# MKE16Z4 register map
Vendor: nxp.com; File version: 1.0
CPU: CM0PLUS r0p0, little endian, no MPU, no FPU, VTOR, 2 interrupt priority bits
Registers are 32-bit, read-write, reset 0x0 unless marked. A register's access mark holds for its fields unless they carry their own. Offsets are from the block's base; [hi:lo] are bit positions; {n}, {i} and the like mark numbered series; 'fields as' and 'values as' point back to an identical list.

## MSCAN — Modular/Scalable Controller Area Network (MSCAN)
Base 0x40024000; register names take the prefix MSCAN_
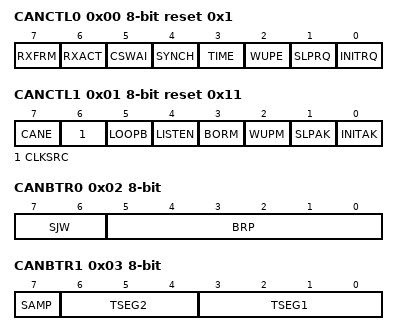
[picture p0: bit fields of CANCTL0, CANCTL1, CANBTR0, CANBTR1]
0x00 CANCTL0 8-bit reset 0x1 — MSCAN Control Register 0
  [7] RXFRM — Received Frame Flag
    0=No valid message was received since last clearing this flag; 1=A valid message was received since last clearing of this flag
  [6] RXACT ro — Receiver Active Status
    0=MSCAN is transmitting or idle; 1=MSCAN is receiving a message, including when arbitration is lost
  [5] CSWAI — CAN Stops in Wait Mode
    0=The module is not affected during wait mode; 1=The module ceases to be clocked during wait mode
  [4] SYNCH ro — Synchronized Status
    0=MSCAN is not synchronized to the CAN bus; 1=MSCAN is synchronized to the CAN bus
  [3] TIME — Timer Enable
    0=Disable internal MSCAN timer; 1=Enable internal MSCAN timer
  [2] WUPE — WakeUp Enable
    0=Wakeup disabled - The MSCAN ignores traffic on CAN; 1=Wakeup enabled - The MSCAN is able to restart
  [1] SLPRQ — Sleep Mode Request
    0=Running - The MSCAN functions normally; 1=Sleep mode request - The MSCAN enters sleep mode when CAN bus idle
  [0] INITRQ — Initialization Mode Request
    0=Normal operation; 1=MSCAN in initialization mode
0x01 CANCTL1 8-bit reset 0x11 — MSCAN Control Register 1
  [7] CANE — MSCAN Enable
    0=MSCAN module is disabled; 1=MSCAN module is enabled
  [6] CLKSRC — MSCAN Clock Source
    0=MSCAN clock source is the oscillator clock; 1=MSCAN clock source is the bus clock
  [5] LOOPB — Loopback Self Test Mode
    0=Loopback self test disabled; 1=Loopback self test enabled
  [4] LISTEN — Listen Only Mode
    0=Normal operation; 1=Listen only mode activated
  [3] BORM — Bus-Off Recovery Mode
    0=Automatic bus-off recovery (see Bosch CAN 2.0A/B protocol specification); 1=Bus-off recovery upon user request
  [2] WUPM — WakeUp Mode
    0=MSCAN wakes on any dominant level on the CAN bus; 1=MSCAN wakes only in case of a dominant pulse on the CAN bus that has a length of Twup
  [1] SLPAK ro — Sleep Mode Acknowledge
    0=Running - The MSCAN operates normally; 1=Sleep mode active - The MSCAN has entered sleep mode
  [0] INITAK ro — Initialization Mode Acknowledge
    0=Running - The MSCAN operates normally; 1=Initialization mode active - The MSCAN has entered initialization mode
0x02 CANBTR0 8-bit — MSCAN Bus Timing Register 0
  [7:6] SJW — Synchronization Jump Width
    0=1 Tq clock cycle; 1=2 Tq clock cycles; 2=3 Tq clock cycle; 3=4 Tq clock cycles
  [5:0] BRP — Baud Rate Prescaler
    0=1; 1=2; 2=BRP_2; 3=BRP_3; 62=63; 63=64
0x03 CANBTR1 8-bit — MSCAN Bus Timing Register 1
  [7] SAMP — Sampling
    0=One sample per bit; 1=Three samples per bit. In this case, PHASE_SEG1 must be at least 2 time quanta (Tq).
  [6:4] TSEG2 — Time Segment 2
    0=1 Tq clock cycle (not valid); {v}={v+1} Tq clock cycles (v=1..7)
  [3:0] TSEG1 — Time Segment 1
    0=1 Tq clock cycle (not valid); 1=2 Tq clock cycles (not valid); 2=3 Tq clock cycles (not valid); 3=4 Tq clock cycles; 14=15 Tq clock cycles; 15=16 Tq clock cycles
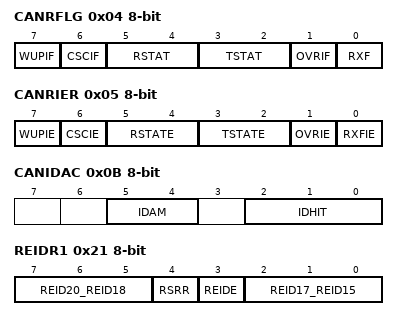
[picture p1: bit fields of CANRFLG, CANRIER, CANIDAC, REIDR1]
0x04 CANRFLG 8-bit — MSCAN Receiver Flag Register
  [7] WUPIF — Wake-Up Interrupt Flag
    0=No wakeup activity observed while in sleep mode; 1=MSCAN detected activity on the CAN bus and requested wakeup
  [6] CSCIF — CAN Status Change Interrupt Flag
    0=No change in CAN bus status occurred since last interrupt; 1=MSCAN changed current CAN bus status
  [5:4] RSTAT ro — Receiver Status
    0=RxOK: 0<=receive error counter<96; 1=RxWRN: 96<=receive error counter<128; 2=RxERR: 128<=receive error counter; 3=Bus-off: 256<=transmit error counter (Redundant Information for the most critical CAN bus status which is "bus-off". This only occurs if the Tx error counter exceeds a number of 255 errors. Bus-off affects the receiver state. As soon as the transmitter leaves its bus-off state the receiver state skips to RxOK too. Refer also to TSTAT[1:0] coding in this register. )
  [3:2] TSTAT ro — Transmitter Status
    0=TxOK: 0<=transmit error counter<96; 1=TxWRN: 96<=transmit error counter<128; 2=TxERR: 128<=transmit error counter<256; 3=Bus-off: 256<=transmit error counter
  [1] OVRIF — Overrun Interrupt Flag
    0=No data overrun condition; 1=A data overrun detected
  [0] RXF — Receive Buffer Full Flag
    0=No new message available within the RxFG; 1=The receiver FIFO is not empty. A new message is available in the RxFG.
0x05 CANRIER 8-bit — MSCAN Receiver Interrupt Enable Register
  [7] WUPIE — WakeUp Interrupt Enable
    0=No interrupt request is generated from this event; 1=A wake-up event causes a Wake-Up interrupt request
  [6] CSCIE — CAN Status Change Interrupt Enable
    0=No interrupt request is generated from this event; 1=A CAN Status Change event causes an error interrupt request
  [5:4] RSTATE — Receiver Status Change Enable
    0=Do not generate any CSCIF interrupt caused by receiver state changes; 1=Generate CSCIF interrupt only if the receiver enters or leaves "bus-off" state. Discard other receiver state changes for generating CSCIF interrupt.; 2=Generate CSCIF interrupt only if the receiver enters or leaves "RxErr" or "bus-off"Bus-off state is only defined for transmitters by the CAN standard (see Bosch CAN 2.0A/B protocol specification). Because the only possible state change for the transmitter from bus-off to TxOK also forces the receiver to skip its current state to RxOK, the coding of the RXSTAT[1:0] flags define an additional bus-off state for the receiver state. Discard other receiver state changes for generating CSCIF interrupt.; 3=Generate CSCIF interrupt on all state changes
  [3:2] TSTATE — Transmitter Status Change Enable
    0=Do not generate any CSCIF interrupt caused by transmitter state changes; 1=Generate CSCIF interrupt only if the transmitter enters or leaves "bus-off" state. Discard other transmitter state changes for generating CSCIF interrupt.; 2=Generate CSCIF interrupt only if the transmitter enters or leaves "TxErr" or "bus-off" state. Discard other transmitter state changes for generating CSCIF interrupt.; 3=Generate CSCIF interrupt on all state changes
  [1] OVRIE — Overrun Interrupt Enable
    0=No interrupt request is generated from this event; 1=An overrun event causes an error interrupt request
  [0] RXFIE — Receiver Full Interrupt Enable
    0=No interrupt request is generated from this event; 1=A receive buffer full (successful message reception) event causes a receiver interrupt request
0x06 CANTFLG 8-bit reset 0x7 — MSCAN Transmitter Flag Register
  [2:0] TXE — Transmitter Buffer Empty
    0=The associated message buffer is full (loaded with a message due for transmission); 1=The associated message buffer is empty (not scheduled)
0x07 CANTIER 8-bit — MSCAN Transmitter Interrupt Enable Register
  [2:0] TXEIE — Transmitter Empty Interrupt Enable
    0=No interrupt request is generated from this event; 1=A transmitter empty (transmit buffer available for transmission) event causes a transmitter empty interrupt request
0x08 CANTARQ 8-bit — MSCAN Transmitter Message Abort Request Register
  [2:0] ABTRQ — Abort Request
    0=No abort request; 1=Abort request pending
0x09 CANTAAK 8-bit ro — MSCAN Transmitter Message Abort Acknowledge Register
  [2:0] ABTAK — Abort Acknowledge
    0=The message was not aborted; 1=The message was aborted
0x0A CANTBSEL 8-bit — MSCAN Transmit Buffer Selection Register
  [2:0] TX — Transmit Buffer Select
    0=The associated message buffer is deselected; 1=The associated message buffer is selected, if lowest numbered bit
0x0B CANIDAC 8-bit — MSCAN Identifier Acceptance Control Register
  [5:4] IDAM — Identifier Acceptance Mode
    0=Two 32-bit acceptance filters; 1=Four 16-bit acceptance filters; 2=Eight 8-bit acceptance filters; 3=Filter closed
  [2:0] IDHIT ro — Identifier Acceptance Hit Indicator
    {v}=Filter {v} hit (v=0..7)
0x0D CANMISC 8-bit — MSCAN Miscellaneous Register
  [0] BOHOLD — Bus-off State Hold Until User Request
    0=Module is not bus-off or recovery has been requested by user in bus-off state; 1=Module is bus-off and holds this state until user request
0x0E CANRXERR 8-bit ro — MSCAN Receive Error Counter
  [7:0] RXERR — Receive Error Counter
0x0F CANTXERR 8-bit ro — MSCAN Transmit Error Counter
  [7:0] TXERR — Transmit Error Counter
{0x10+i} CANIDAR{i} 8-bit (i=0..3) — MSCAN Identifier Acceptance Register n of First Bank
  [7:0] AC — Acceptance Code Bits
{0x14+i} CANIDMR{i} 8-bit (i=0..3) — MSCAN Identifier Mask Register n of First Bank
  [7:0] AM — Acceptance Mask Bits
    0=Match corresponding acceptance code register and identifier bits; 1=Ignore corresponding acceptance code register bit
{0x14+i} CANIDAR{i} 8-bit (i=4..7) — MSCAN Identifier Acceptance Register n of Second Bank
  [7:0] AC — Acceptance Code Bits
{0x18+i} CANIDMR{i} 8-bit (i=4..7) — MSCAN Identifier Mask Register n of Second Bank
  fields as CANIDMR0
0x20 REIDR0 8-bit ro reset not defined (REIDR0_RSIDR0 view) — Receive Extended Identifier Register 0
  [7:0] REID28_REID21 — Extended Format Identifier
0x20 RSIDR0 8-bit ro reset not defined (REIDR0_RSIDR0 view) — Receive Standard Identifier Register 0
  [7:0] RSID10_RSID3 — Standard Format Identifier
0x21 REIDR1 8-bit ro reset not defined (REIDR1_RSIDR1 view) — Receive Extended Identifier Register 1
  [7:5] REID20_REID18 — Extended Format Identifier 20-18
  [4] RSRR — Substitute Remote Request
  [3] REIDE — ID Extended
    0=Standard format (11 bit); 1=Extended format (29 bit)
  [2:0] REID17_REID15 — Extended Format Identifier 17-15
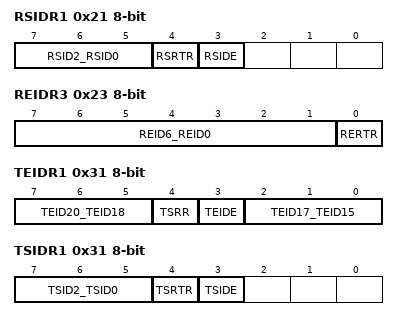
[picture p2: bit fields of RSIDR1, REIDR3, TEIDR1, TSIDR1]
0x21 RSIDR1 8-bit ro reset not defined (REIDR1_RSIDR1 view) — Receive Standard Identifier Register 1
  [7:5] RSID2_RSID0 — Standard Format Identifier 2-0
  [4] RSRTR — Remote Transmission Request
    0=Data frame; 1=Remote frame
  [3] RSIDE — ID Extended
    0=Standard format (11 bit); 1=Extended format (29 bit)
0x22 REIDR2 8-bit ro reset not defined — Receive Extended Identifier Register 2
  [7:0] REID14_REID7 — Extended Format Identifier 14-7
0x23 REIDR3 8-bit ro reset not defined — Receive Extended Identifier Register 3
  [7:1] REID6_REID0 — Extended Format Identifier 6-0
  [0] RERTR — Remote Transmission Request
    0=Data frame; 1=Remote frame
{0x24+i} REDSR{i} (i=0..7) 8-bit ro reset not defined — Receive Extended Data Segment Register N
  [7:0] RDB — Data Bits
0x2C RDLR 8-bit ro reset not defined — Receive Data Length Register
  [3:0] RDLC — Data Length Code Bits
    {v}={v} (v=0..8)
0x2E RTSRH 8-bit ro reset not defined — Receive Time Stamp Register High
  [7:0] RTS — Time Stamp
0x2F RTSRL 8-bit ro reset not defined — Receive Time Stamp Register Low
  [7:0] RTS — Time Stamp
0x30 TEIDR0 8-bit reset not defined (TEIDR0_TSIDR0 view) — Transmit Extended Identifier Register 0
  [7:0] TEID28_TEID21 — Extended Format Identifier
0x30 TSIDR0 8-bit reset not defined (TEIDR0_TSIDR0 view) — Transmit Standard Identifier Register 0
  [7:0] TSID10_TSID3 — Standard Format Identifier
0x31 TEIDR1 8-bit reset not defined (TEIDR1_TSIDR1 view) — Transmit Extended Identifier Register 1
  [7:5] TEID20_TEID18 — Extended Format Identifier 20-18
  [4] TSRR — Substitute Remote Request
  [3] TEIDE — ID Extended
    0=Standard format (11 bit); 1=Extended format (29 bit)
  [2:0] TEID17_TEID15 — Extended Format Identifier 17-15
0x31 TSIDR1 8-bit reset not defined (TEIDR1_TSIDR1 view) — Transmit Standard Identifier Register 1
  [7:5] TSID2_TSID0 — Standard Format Identifier 2-0
  [4] TSRTR — Remote Transmission Request
    0=Data frame; 1=Remote frame
  [3] TSIDE — ID Extended
    0=Standard format (11 bit); 1=Extended format (29 bit)
0x32 TEIDR2 8-bit reset not defined — Transmit Extended Identifier Register 2
  [7:0] TEID14_TEID7 — Extended Format Identifier 14-7
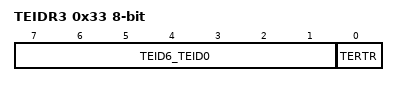
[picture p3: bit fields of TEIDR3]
0x33 TEIDR3 8-bit reset not defined — Transmit Extended Identifier Register 3
  [7:1] TEID6_TEID0 — Extended Format Identifier 6-0
  [0] TERTR — Remote Transmission Request
    0=Data frame; 1=Remote frame
{0x34+i} TEDSR{i} (i=0..7) 8-bit reset not defined — Transmit Extended Data Segment Register N
  [7:0] TDB — Data Bits
0x3C TDLR 8-bit reset not defined — Transmit Data Length Register
  [3:0] TDLC — Data Length Code Bits
    {v}={v} (v=0..8)
0x3D TBPR 8-bit reset not defined — Transmit Buffer Priority Register
  [7:0] PRIO — Priority
0x3E TTSRH 8-bit ro reset not defined — Transmit Time Stamp Register High
  [7:0] TTS — Time Stamp
0x3F TTSRL 8-bit ro reset not defined — Transmit Time Stamp Register Low
  [7:0] TTS — Time Stamp
